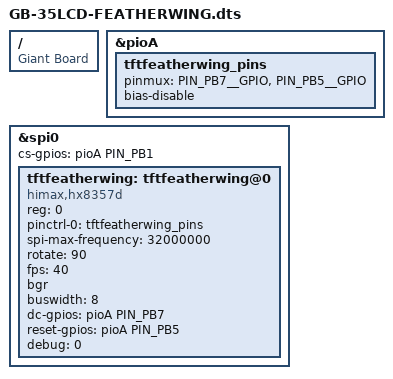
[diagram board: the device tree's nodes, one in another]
/dts-v1/;
/plugin/;

#include "sama5d2-pinfunc.h"

/ {
	compatible = "Giant Board";

	fragment@0 {
		target = <&pioA>;
		__overlay__ {
			tftfeatherwing_pins: tftfeatherwing_pins {
				pinmux = <PIN_PB7__GPIO>,
						 <PIN_PB5__GPIO>;
				bias-disable;
			};
		};
	};

	fragment@1 {
		target = <&spi0>;
		__overlay__ {
			#address-cells = <1>;
			#size-cells = <0>;
			cs-gpios = <&pioA PIN_PB1 0>;
			status = "okay";
			tftfeatherwing: tftfeatherwing@0{
				compatible = "himax,hx8357d";
				reg = <0>;
				pinctrl-names = "default";
				pinctrl-0 = <&tftfeatherwing_pins>;
				
				spi-max-frequency = <32000000>;
				rotate = <90>;
				fps = <40>;
				bgr;
				buswidth = <8>;
				dc-gpios = <&pioA PIN_PB7 0>;
				reset-gpios = <&pioA PIN_PB5 0>;
				debug = <0>;
			};
		};
	};
};
